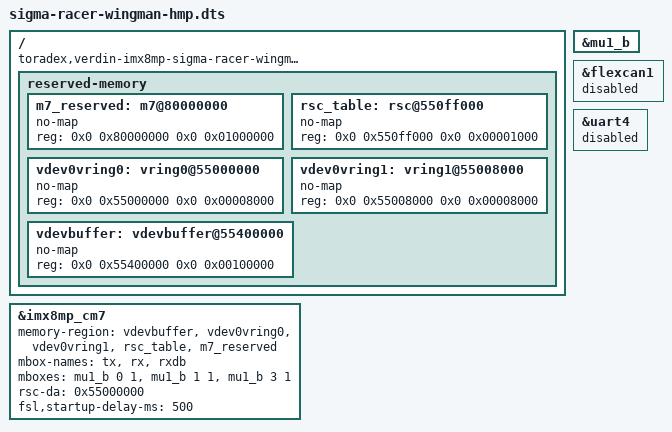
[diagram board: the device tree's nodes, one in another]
// Sigma Racer Wingman — heterogeneous multiprocessing overlay for Verdin iMX8M Plus.
// Applies on top of the Toradex BSP device tree.
/dts-v1/;
/plugin/;

#include <dt-bindings/clock/imx8mp-clock.h>

/ {
	compatible = "toradex,verdin-imx8mp-sigma-racer-wingman-hmp";

	fragment@0 {
		target-path = "/";
		__overlay__ {
			reserved-memory {
				#address-cells = <2>;
				#size-cells = <2>;
				ranges;

				m7_reserved: m7@80000000 {
					no-map;
					reg = <0x0 0x80000000 0x0 0x01000000>;
				};

				rsc_table: rsc@550ff000 {
					no-map;
					reg = <0x0 0x550ff000 0x0 0x00001000>;
				};

				vdev0vring0: vring0@55000000 {
					no-map;
					reg = <0x0 0x55000000 0x0 0x00008000>;
				};

				vdev0vring1: vring1@55008000 {
					no-map;
					reg = <0x0 0x55008000 0x0 0x00008000>;
				};

				vdevbuffer: vdevbuffer@55400000 {
					no-map;
					reg = <0x0 0x55400000 0x0 0x00100000>;
				};
			};
		};
	};

	fragment@1 {
		target = <&mu1_b>;
		__overlay__ {
			status = "okay";
		};
	};

	fragment@2 {
		target = <&imx8mp_cm7>;
		__overlay__ {
			memory-region = <&vdevbuffer>, <&vdev0vring0>, <&vdev0vring1>,
					<&rsc_table>, <&m7_reserved>;
			mbox-names = "tx", "rx", "rxdb";
			mboxes = <&mu1_b 0 1>, <&mu1_b 1 1>, <&mu1_b 3 1>;
			rsc-da = <0x55000000>;
			fsl,startup-delay-ms = <500>;
		};
	};

	/* FLEXCAN1 is owned by the M7 safety core — Linux uses FLEXCAN2 (can1). */
	fragment@3 {
		target = <&flexcan1>;
		__overlay__ {
			status = "disabled";
		};
	};

	/* UART4 is the M7 debug console — keep Linux off these pins. */
	fragment@4 {
		target = <&uart4>;
		__overlay__ {
			status = "disabled";
		};
	};
};
